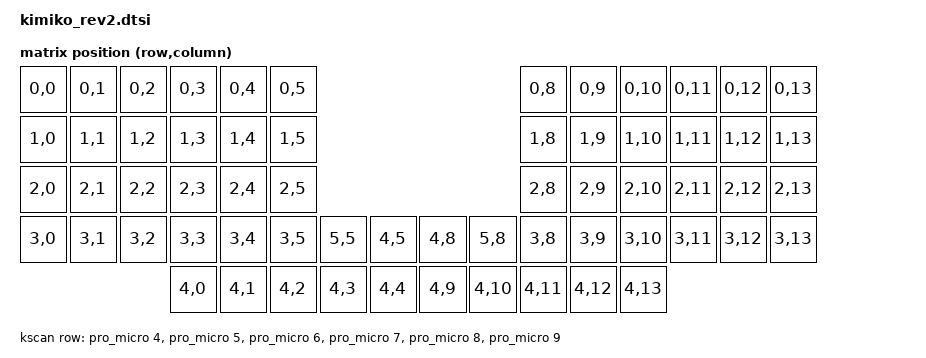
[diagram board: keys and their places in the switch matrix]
// This file was generated from a template. Edit it to match your keyboard.
// See https://zmk.dev/docs/development/hardware-integration/new-shield for more
// instructions.

#include <dt-bindings/zmk/matrix_transform.h>

#include "kimiko_rev2-layouts.dtsi"

/ {
    chosen {
        zmk,physical-layout = &default_layout;
    };

    kscan: kscan {
        // If the hardware does not use a switch matrix, change this to the
        // appropriate driver and update the properties below to match.
        // See https://zmk.dev/docs/config/kscan for supported key scan drivers.
        compatible = "zmk,kscan-gpio-matrix";
        // Set this to "col2row" or "row2col" to match the hardware. If using
        // "row2col", change the col-gpios in the _left.overlay and _right.overlay
        // files to (GPIO_ACTIVE_HIGH | GPIO_PULL_DOWN) and the row-gpios here to
        // GPIO_ACTIVE_HIGH.
        diode-direction = "col2row";
        wakeup-source;

        // Replace these comments with the GPIO pins in the matrix.
        // See https://zmk.dev/docs/development/hardware-integration/new-shield#shield-overlays
        row-gpios
            = <&pro_micro 4 (GPIO_ACTIVE_HIGH | GPIO_PULL_DOWN)>  // D4 (ROW0)
            , <&pro_micro 5 (GPIO_ACTIVE_HIGH | GPIO_PULL_DOWN)>  // C6 (ROW1)
            , <&pro_micro 6 (GPIO_ACTIVE_HIGH | GPIO_PULL_DOWN)>  // D7 (ROW2)
            , <&pro_micro 7 (GPIO_ACTIVE_HIGH | GPIO_PULL_DOWN)>  // E6 (ROW3)
            , <&pro_micro 8 (GPIO_ACTIVE_HIGH | GPIO_PULL_DOWN)>  // B4 (ROW4)
            , <&pro_micro 9 (GPIO_ACTIVE_HIGH | GPIO_PULL_DOWN)>  // B5 (ROW5)
            ;
    };

    default_transform: default_transform {
        // See https://zmk.dev/docs/development/hardware-integration/new-shield#matrix-transform
        // for how to configure this
        compatible = "zmk,matrix-transform";
        columns = <16>;
        rows = <5>;

        // | SW6  | SW5  | SW4  | SW3  | SW2  | SW1  |                             | SW1  | SW2  | SW3  | SW4  | SW5  | SW6  |
        // | SW12 | SW11 | SW10 | SW9  | SW8  | SW7  |                             | SW7  | SW8  | SW9  | SW10 | SW11 | SW12 |
        // | SW18 | SW17 | SW16 | SW15 | SW14 | SW13 |                             | SW13 | SW14 | SW15 | SW16 | SW17 | SW18 |
        // | SW24 | SW23 | SW22 | SW21 | SW20 | SW19 | SW25 | SW26 | | SW26 | SW25 | SW19 | SW20 | SW21 | SW22 | SW23 | SW24 |
        //                      | SW31 | SW30 | SW29 | SW28 | SW27 | | SW27 | SW28 | SW29 | SW30 | SW31 |

        map = <
            RC(0,0) RC(0,1) RC(0,2) RC(0,3) RC(0,4) RC(0,5)                                  RC(0,8)  RC(0,9)  RC(0,10) RC(0,11) RC(0,12) RC(0,13)
            RC(1,0) RC(1,1) RC(1,2) RC(1,3) RC(1,4) RC(1,5)                                  RC(1,8)  RC(1,9)  RC(1,10) RC(1,11) RC(1,12) RC(1,13)
            RC(2,0) RC(2,1) RC(2,2) RC(2,3) RC(2,4) RC(2,5)                                  RC(2,8)  RC(2,9)  RC(2,10) RC(2,11) RC(2,12) RC(2,13)
            RC(3,0) RC(3,1) RC(3,2) RC(3,3) RC(3,4) RC(3,5) RC(5,5) RC(4,5) RC(4,8) RC(5,8)  RC(3,8)  RC(3,9)  RC(3,10) RC(3,11) RC(3,12) RC(3,13)
                                    RC(4,0) RC(4,1) RC(4,2) RC(4,3) RC(4,4) RC(4,9) RC(4,10) RC(4,11) RC(4,12) RC(4,13)
            >;
    };
};
